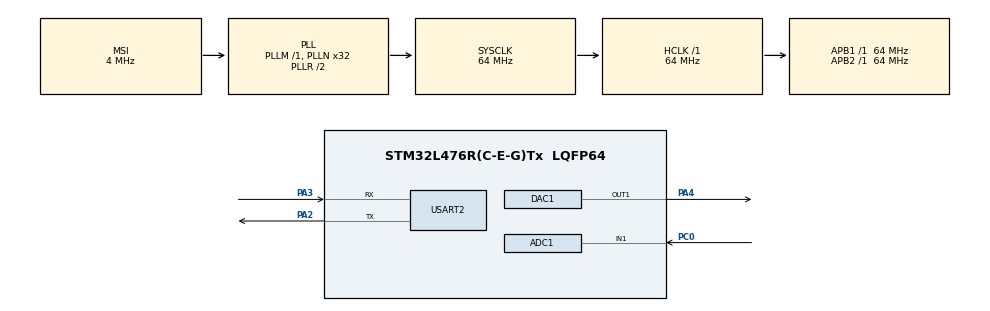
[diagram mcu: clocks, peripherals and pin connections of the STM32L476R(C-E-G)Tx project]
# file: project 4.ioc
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ADC1.Channel-1\#ChannelRegularConversion=ADC_CHANNEL_1
ADC1.NbrOfConversionFlag=1
ADC1.OffsetNumber-1\#ChannelRegularConversion=ADC_OFFSET_NONE
ADC1.Rank-1\#ChannelRegularConversion=1
ADC1.SamplingTime-1\#ChannelRegularConversion=ADC_SAMPLETIME_2CYCLES_5
ADC1.master=1
DAC1.DAC_Trigger-DAC_OUT1=DAC_TRIGGER_NONE
Mcu.Family=STM32L4
Mcu.Name=STM32L476R(C-E-G)Tx
Mcu.Package=LQFP64
NVIC.ADC1_2_IRQn=true\:0\:0\:false\:false\:true\:true\:true
NVIC.PriorityGroup=NVIC_PRIORITYGROUP_4
NVIC.TIM2_IRQn=true\:0\:0\:false\:false\:true\:true\:true
PA2.Mode=Asynchronous
PA2.Signal=USART2_TX
PA3.Mode=Asynchronous
PA3.Signal=USART2_RX
PA4.Signal=COMP_DAC11_group
PC0.Signal=ADCx_IN1
ProjectManager.HeapSize=0x200
ProjectManager.StackSize=0x400
ProjectManager.TargetToolchain=STM32CubeIDE
RCC.ADCFreq_Value=32000000
RCC.AHBFreq_Value=64000000
RCC.APB1Freq_Value=64000000
RCC.APB1TimFreq_Value=64000000
RCC.APB2Freq_Value=64000000
RCC.APB2TimFreq_Value=64000000
RCC.CortexFreq_Value=64000000
RCC.HCLKFreq_Value=64000000
RCC.HSE_VALUE=8000000
RCC.HSI_VALUE=16000000
RCC.LSE_VALUE=32768
RCC.MSI_VALUE=4000000
RCC.PLLN=32
RCC.PLLSAI1N=16
RCC.SYSCLKFreq_VALUE=64000000
RCC.SYSCLKSource=RCC_SYSCLKSOURCE_PLLCLK
RCC.USBFreq_Value=32000000
RCC.VCOOutputFreq_Value=128000000
SH.ADCx_IN1.0=ADC1_IN1,IN1-Single-Ended
SH.COMP_DAC11_group.0=DAC1_OUT1,DAC_OUT1
TIM2.Period=88
TIM2.Prescaler=88
TIM2.TIM_MasterOutputTrigger=TIM_TRGO_UPDATE
USART2.VirtualMode-Asynchronous=VM_ASYNC
VP_TIM2_VS_ClockSourceINT.Mode=Internal
board=custom

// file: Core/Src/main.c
/* USER CODE BEGIN Header */
/**
  ******************************************************************************
  * @file           : main.c
  * @brief          : Main program body
  ******************************************************************************
  * @attention
  *
  * <h2><center>&copy; Copyright (c) 2021 STMicroelectronics.
  * All rights reserved.</center></h2>
  *
  * This software component is licensed by ST under BSD 3-Clause license,
  * the "License"; You may not use this file except in compliance with the
  * License. You may obtain a copy of the License at:
  *                        opensource.org/licenses/BSD-3-Clause
  *
  ******************************************************************************
  */
/* USER CODE END Header */
#include "main.h"

ADC_HandleTypeDef hadc1;

DAC_HandleTypeDef hdac1;

TIM_HandleTypeDef htim2;

UART_HandleTypeDef huart2;

void SystemClock_Config(void);
static void MX_GPIO_Init(void);
static void MX_DAC1_Init(void);
static void MX_USART2_UART_Init(void);
static void MX_TIM2_Init(void);
static void MX_ADC1_Init(void);
/* USER CODE BEGIN PFP */
void print(void){
	char msg[100];
	int x = get_cnt();
	if(HAL_GetTick()<1000 || (HAL_GetTick()<11000 && HAL_GetTick()>10000)){//while(get_cnt() == x && get_idx()){
		int len = sprintf(msg, "%d, %d, %lu\r\n", get_dac(), get_adc(),HAL_GetTick());
		USART_Write(huart2.Instance, msg, len);
	}
	return;
}
/* USER CODE END PFP */

int main(void)
{
  /* USER CODE BEGIN 1 */
	char* msg;
  /* USER CODE END 1 */

  /* MCU Configuration--------------------------------------------------------*/

  /* Reset of all peripherals, Initializes the Flash interface and the Systick. */
  HAL_Init();

  /* Configure the system clock */
  SystemClock_Config();

  /* Initialize all configured peripherals */
  MX_GPIO_Init();
  MX_DAC1_Init();
  MX_USART2_UART_Init();
  MX_TIM2_Init();
  MX_ADC1_Init();
  /* USER CODE BEGIN 2 */
  populate_array();
  HAL_TIM_Base_Start_IT(&htim2);
  HAL_DAC_Start(&hdac1, DAC_CHANNEL_1);
 // HAL_ADCEx_Calibration_Start(&hadc1, ADC_SINGLE_ENDED);

  /* USER CODE END 2 */

  /* Infinite loop */
  while (1)
  {
	 print();
  }
}

void SystemClock_Config(void)
{
  RCC_OscInitTypeDef RCC_OscInitStruct = {0};
  RCC_ClkInitTypeDef RCC_ClkInitStruct = {0};

  /** Configure the main internal regulator output voltage
  */
  if (HAL_PWREx_ControlVoltageScaling(PWR_REGULATOR_VOLTAGE_SCALE1) != HAL_OK)
  {
    Error_Handler();
  }
  /** Initializes the RCC Oscillators according to the specified parameters
  * in the RCC_OscInitTypeDef structure.
  */
  RCC_OscInitStruct.OscillatorType = RCC_OSCILLATORTYPE_MSI;
  RCC_OscInitStruct.MSIState = RCC_MSI_ON;
  RCC_OscInitStruct.MSICalibrationValue = 0;
  RCC_OscInitStruct.MSIClockRange = RCC_MSIRANGE_6;
  RCC_OscInitStruct.PLL.PLLState = RCC_PLL_ON;
  RCC_OscInitStruct.PLL.PLLSource = RCC_PLLSOURCE_MSI;
  RCC_OscInitStruct.PLL.PLLM = 1;
  RCC_OscInitStruct.PLL.PLLN = 32;
  RCC_OscInitStruct.PLL.PLLP = RCC_PLLP_DIV7;
  RCC_OscInitStruct.PLL.PLLQ = RCC_PLLQ_DIV2;
  RCC_OscInitStruct.PLL.PLLR = RCC_PLLR_DIV2;
  if (HAL_RCC_OscConfig(&RCC_OscInitStruct) != HAL_OK)
  {
    Error_Handler();
  }
  /** Initializes the CPU, AHB and APB buses clocks
  */
  RCC_ClkInitStruct.ClockType = RCC_CLOCKTYPE_HCLK|RCC_CLOCKTYPE_SYSCLK
                              |RCC_CLOCKTYPE_PCLK1|RCC_CLOCKTYPE_PCLK2;
  RCC_ClkInitStruct.SYSCLKSource = RCC_SYSCLKSOURCE_PLLCLK;
  RCC_ClkInitStruct.AHBCLKDivider = RCC_SYSCLK_DIV1;
  RCC_ClkInitStruct.APB1CLKDivider = RCC_HCLK_DIV1;
  RCC_ClkInitStruct.APB2CLKDivider = RCC_HCLK_DIV1;

  if (HAL_RCC_ClockConfig(&RCC_ClkInitStruct, FLASH_LATENCY_3) != HAL_OK)
  {
    Error_Handler();
  }
}

static void MX_ADC1_Init(void)
{

  ADC_MultiModeTypeDef multimode = {0};
  ADC_ChannelConfTypeDef sConfig = {0};

  /** Common config
  */
  hadc1.Instance = ADC1;
  hadc1.Init.ClockPrescaler = ADC_CLOCK_ASYNC_DIV1;
  hadc1.Init.Resolution = ADC_RESOLUTION_12B;
  hadc1.Init.DataAlign = ADC_DATAALIGN_RIGHT;
  hadc1.Init.ScanConvMode = ADC_SCAN_DISABLE;
  hadc1.Init.EOCSelection = ADC_EOC_SINGLE_CONV;
  hadc1.Init.LowPowerAutoWait = DISABLE;
  hadc1.Init.ContinuousConvMode = DISABLE;
  hadc1.Init.NbrOfConversion = 1;
  hadc1.Init.DiscontinuousConvMode = DISABLE;
  hadc1.Init.ExternalTrigConv = ADC_SOFTWARE_START;
  hadc1.Init.ExternalTrigConvEdge = ADC_EXTERNALTRIGCONVEDGE_NONE;
  hadc1.Init.DMAContinuousRequests = DISABLE;
  hadc1.Init.Overrun = ADC_OVR_DATA_PRESERVED;
  hadc1.Init.OversamplingMode = DISABLE;
  if (HAL_ADC_Init(&hadc1) != HAL_OK)
  {
    Error_Handler();
  }
  /** Configure the ADC multi-mode
  */
  multimode.Mode = ADC_MODE_INDEPENDENT;
  if (HAL_ADCEx_MultiModeConfigChannel(&hadc1, &multimode) != HAL_OK)
  {
    Error_Handler();
  }
  /** Configure Regular Channel
  */
  sConfig.Channel = ADC_CHANNEL_1;
  sConfig.Rank = ADC_REGULAR_RANK_1;
  sConfig.SamplingTime = ADC_SAMPLETIME_2CYCLES_5;
  sConfig.SingleDiff = ADC_SINGLE_ENDED;
  sConfig.OffsetNumber = ADC_OFFSET_NONE;
  sConfig.Offset = 0;
  if (HAL_ADC_ConfigChannel(&hadc1, &sConfig) != HAL_OK)
  {
    Error_Handler();
  }

}

static void MX_DAC1_Init(void)
{

  DAC_ChannelConfTypeDef sConfig = {0};

  /** DAC Initialization
  */
  hdac1.Instance = DAC1;
  if (HAL_DAC_Init(&hdac1) != HAL_OK)
  {
    Error_Handler();
  }
  /** DAC channel OUT1 config
  */
  sConfig.DAC_SampleAndHold = DAC_SAMPLEANDHOLD_DISABLE;
  sConfig.DAC_Trigger = DAC_TRIGGER_NONE;
  sConfig.DAC_OutputBuffer = DAC_OUTPUTBUFFER_ENABLE;
  sConfig.DAC_ConnectOnChipPeripheral = DAC_CHIPCONNECT_DISABLE;
  sConfig.DAC_UserTrimming = DAC_TRIMMING_FACTORY;
  if (HAL_DAC_ConfigChannel(&hdac1, &sConfig, DAC_CHANNEL_1) != HAL_OK)
  {
    Error_Handler();
  }

}

static void MX_TIM2_Init(void)
{

  TIM_ClockConfigTypeDef sClockSourceConfig = {0};
  TIM_MasterConfigTypeDef sMasterConfig = {0};

  htim2.Instance = TIM2;
  htim2.Init.Prescaler = 88;
  htim2.Init.CounterMode = TIM_COUNTERMODE_UP;
  htim2.Init.Period = 88;
  htim2.Init.ClockDivision = TIM_CLOCKDIVISION_DIV1;
  htim2.Init.AutoReloadPreload = TIM_AUTORELOAD_PRELOAD_DISABLE;
  if (HAL_TIM_Base_Init(&htim2) != HAL_OK)
  {
    Error_Handler();
  }
  sClockSourceConfig.ClockSource = TIM_CLOCKSOURCE_INTERNAL;
  if (HAL_TIM_ConfigClockSource(&htim2, &sClockSourceConfig) != HAL_OK)
  {
    Error_Handler();
  }
  sMasterConfig.MasterOutputTrigger = TIM_TRGO_UPDATE;
  sMasterConfig.MasterSlaveMode = TIM_MASTERSLAVEMODE_DISABLE;
  if (HAL_TIMEx_MasterConfigSynchronization(&htim2, &sMasterConfig) != HAL_OK)
  {
    Error_Handler();
  }

}

static void MX_USART2_UART_Init(void)
{

  huart2.Instance = USART2;
  huart2.Init.BaudRate = 115200;
  huart2.Init.WordLength = UART_WORDLENGTH_8B;
  huart2.Init.StopBits = UART_STOPBITS_1;
  huart2.Init.Parity = UART_PARITY_NONE;
  huart2.Init.Mode = UART_MODE_TX_RX;
  huart2.Init.HwFlowCtl = UART_HWCONTROL_NONE;
  huart2.Init.OverSampling = UART_OVERSAMPLING_16;
  huart2.Init.OneBitSampling = UART_ONE_BIT_SAMPLE_DISABLE;
  huart2.AdvancedInit.AdvFeatureInit = UART_ADVFEATURE_NO_INIT;
  if (HAL_UART_Init(&huart2) != HAL_OK)
  {
    Error_Handler();
  }

}

static void MX_GPIO_Init(void)
{

  /* GPIO Ports Clock Enable */
  __HAL_RCC_GPIOC_CLK_ENABLE();
  __HAL_RCC_GPIOA_CLK_ENABLE();

}

void Error_Handler(void)
{
  __disable_irq();
  while (1)
  {
  }
}

/************************ (C) COPYRIGHT STMicroelectronics *****END OF FILE****/
